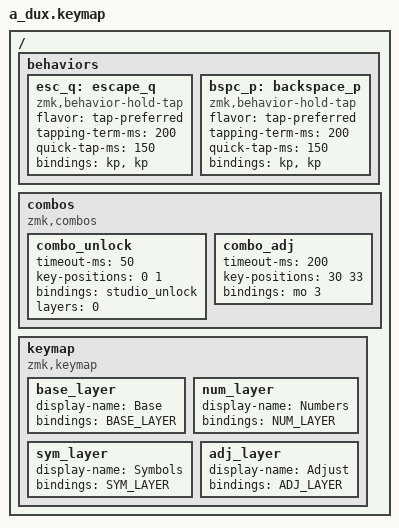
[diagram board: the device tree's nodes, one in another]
/*
 * A_dux Keymap - Using Generic 3x5 Layout
 * 
 * This keymap automatically uses the shared generic_3x5_layers.dtsi
 * Edit config/generic_3x5.keymap with keymap-editor to update all boards
 */

#include <behaviors.dtsi>
#include <dt-bindings/zmk/bt.h>
#include <dt-bindings/zmk/ext_power.h>
#include <dt-bindings/zmk/keys.h>
#include <dt-bindings/zmk/outputs.h>

// Include the shared layer definitions FIRST
#include "generic_3x5_layers.dtsi"

/ {
    behaviors {
        esc_q: escape_q {
            compatible = "zmk,behavior-hold-tap";
            #binding-cells = <2>;
            flavor = "tap-preferred";
            tapping-term-ms = <200>;
            quick-tap-ms = <150>;
            bindings = <&kp>, <&kp>;
        };
        
        bspc_p: backspace_p {
            compatible = "zmk,behavior-hold-tap";
            #binding-cells = <2>;
            flavor = "tap-preferred";
            tapping-term-ms = <200>;
            quick-tap-ms = <150>;
            bindings = <&kp>, <&kp>;
        };
    };

    combos {
        compatible = "zmk,combos";

        combo_unlock {
            timeout-ms = <50>;
            key-positions = <0 1>;
            bindings = <&studio_unlock>;
            layers = <0>;
        };

        combo_adj {
            timeout-ms = <200>;
            key-positions = <30 33>;
            bindings = <&mo 3>;
        };
    };

    keymap {
        compatible = "zmk,keymap";

        base_layer {
            display-name = "Base";
            bindings = <
                BASE_LAYER
            >;
        };

        num_layer {
            display-name = "Numbers";
            bindings = <
                NUM_LAYER
            >;
        };

        sym_layer {
            display-name = "Symbols";
            bindings = <
                SYM_LAYER
            >;
        };

        adj_layer {
            display-name = "Adjust";
            bindings = <
                ADJ_LAYER
            >;
        };
    };
};
